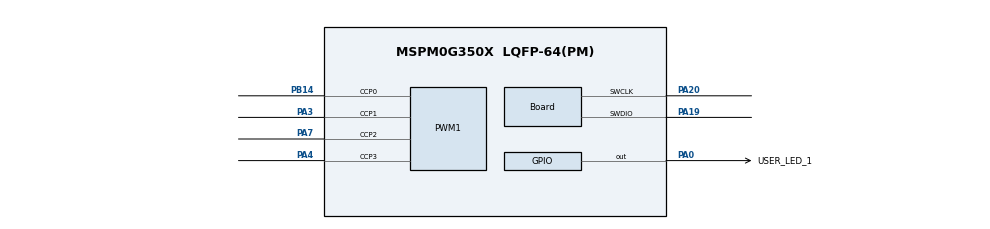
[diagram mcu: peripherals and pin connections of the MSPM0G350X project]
/**
 * @cliArgs --device "MSPM0G350X" --package "LQFP-64(PM)" --part "Default" --product "mspm0_sdk@2.01.00.03"
 * @versions {"tool":"1.20.0+3587"}
 */

/**
 * Import the modules used in this configuration.
 */
const Board         = scripting.addModule("/ti/driverlib/Board");
const GPIO          = scripting.addModule("/ti/driverlib/GPIO", {}, false);
const GPIO1         = GPIO.addInstance();
const GPIO2         = GPIO.addInstance();
const GPIO3         = GPIO.addInstance();
const PWM           = scripting.addModule("/ti/driverlib/PWM", {}, false);
const PWM1          = PWM.addInstance();
const SYSCTL        = scripting.addModule("/ti/driverlib/SYSCTL");
const TIMER         = scripting.addModule("/ti/driverlib/TIMER", {}, false);
const TIMER1        = TIMER.addInstance();
const ProjectConfig = scripting.addModule("/ti/project_config/ProjectConfig");

/**
 * Write custom configuration values to the imported modules.
 */
Board.peripheral.$assign          = "DEBUGSS";
Board.peripheral.swclkPin.$assign = "PA20";
Board.peripheral.swdioPin.$assign = "PA19";

GPIO1.port                           = "PORTA";
GPIO1.$name                          = "GPIO_LEDS_PORT";
GPIO1.portSegment                    = "Lower";
GPIO1.associatedPins[0].initialValue = "SET";
GPIO1.associatedPins[0].$name        = "USER_LED_1";
GPIO1.associatedPins[0].assignedPin  = "0";
GPIO1.associatedPins[0].pin.$assign  = "PA0";

GPIO2.$name                         = "GPIO_RGB";
GPIO2.port                          = "PORTB";
GPIO2.portSegment                   = "Upper";
GPIO2.associatedPins.create(3);
GPIO2.associatedPins[0].$name       = "RED";
GPIO2.associatedPins[0].assignedPin = "26";
GPIO2.associatedPins[1].$name       = "GREEN";
GPIO2.associatedPins[1].assignedPin = "27";
GPIO2.associatedPins[2].$name       = "BLUE";
GPIO2.associatedPins[2].assignedPin = "22";

GPIO3.$name                              = "GPIO_KEY";
GPIO3.port                               = "PORTB";
GPIO3.associatedPins.create(3);
GPIO3.associatedPins[0].$name            = "KEY_1";
GPIO3.associatedPins[0].direction        = "INPUT";
GPIO3.associatedPins[0].assignedPin      = "21";
GPIO3.associatedPins[0].internalResistor = "PULL_UP";
GPIO3.associatedPins[1].assignedPin      = "23";
GPIO3.associatedPins[1].$name            = "KEY_2";
GPIO3.associatedPins[1].direction        = "INPUT";
GPIO3.associatedPins[1].internalResistor = "PULL_UP";
GPIO3.associatedPins[2].assignedPin      = "24";
GPIO3.associatedPins[2].$name            = "KEY_3";
GPIO3.associatedPins[2].direction        = "INPUT";
GPIO3.associatedPins[2].internalResistor = "PULL_UP";

PWM1.ccIndex                            = [0,1,2,3];
PWM1.clockPrescale                      = 32;
PWM1.pwmMode                            = "EDGE_ALIGN_UP";
PWM1.$name                              = "CAR_PWM0";
PWM1.peripheral.$assign                 = "TIMA0";
PWM1.peripheral.ccp0Pin.$assign         = "PB14";
PWM1.peripheral.ccp1Pin.$assign         = "PA3";
PWM1.peripheral.ccp2Pin.$assign         = "PA7";
PWM1.peripheral.ccp3Pin.$assign         = "PA4";
PWM1.PWM_CHANNEL_0.$name                = "ti_driverlib_pwm_PWMTimerCC0";
PWM1.PWM_CHANNEL_1.$name                = "ti_driverlib_pwm_PWMTimerCC1";
PWM1.ccp0PinConfig.$name                = "ti_driverlib_gpio_GPIOPinGeneric0";
PWM1.ccp0PinConfig.direction            = scripting.forceWrite("OUTPUT");
PWM1.ccp0PinConfig.hideOutputInversion  = scripting.forceWrite(false);
PWM1.ccp0PinConfig.onlyInternalResistor = scripting.forceWrite(false);
PWM1.ccp0PinConfig.passedPeripheralType = scripting.forceWrite("Digital");
PWM1.ccp1PinConfig.$name                = "ti_driverlib_gpio_GPIOPinGeneric1";
PWM1.ccp1PinConfig.direction            = scripting.forceWrite("OUTPUT");
PWM1.ccp1PinConfig.hideOutputInversion  = scripting.forceWrite(false);
PWM1.ccp1PinConfig.onlyInternalResistor = scripting.forceWrite(false);
PWM1.ccp1PinConfig.passedPeripheralType = scripting.forceWrite("Digital");
PWM1.PWM_CHANNEL_2.$name                = "ti_driverlib_pwm_PWMTimerCC2";
PWM1.PWM_CHANNEL_2.invert               = true;
PWM1.PWM_CHANNEL_3.$name                = "ti_driverlib_pwm_PWMTimerCC3";
PWM1.PWM_CHANNEL_3.invert               = true;
PWM1.ccp2PinConfig.$name                = "ti_driverlib_gpio_GPIOPinGeneric2";
PWM1.ccp2PinConfig.direction            = scripting.forceWrite("OUTPUT");
PWM1.ccp2PinConfig.hideOutputInversion  = scripting.forceWrite(false);
PWM1.ccp2PinConfig.onlyInternalResistor = scripting.forceWrite(false);
PWM1.ccp2PinConfig.passedPeripheralType = scripting.forceWrite("Digital");
PWM1.ccp3PinConfig.$name                = "ti_driverlib_gpio_GPIOPinGeneric3";
PWM1.ccp3PinConfig.direction            = scripting.forceWrite("OUTPUT");
PWM1.ccp3PinConfig.hideOutputInversion  = scripting.forceWrite(false);
PWM1.ccp3PinConfig.onlyInternalResistor = scripting.forceWrite(false);
PWM1.ccp3PinConfig.passedPeripheralType = scripting.forceWrite("Digital");

SYSCTL.clockTreeEn = true;

TIMER1.$name              = "TIMER_0";
TIMER1.interrupts         = ["ZERO"];
TIMER1.timerMode          = "PERIODIC";
TIMER1.timerPeriod        = "1ms";
TIMER1.peripheral.$assign = "TIMG0";

ProjectConfig.deviceSpin = "MSPM0G3507";

/**
 * Pinmux solution for unlocked pins/peripherals. This ensures that minor changes to the automatic solver in a future
 * version of the tool will not impact the pinmux you originally saw.  These lines can be completely deleted in order to
 * re-solve from scratch.
 */
GPIO2.associatedPins[0].pin.$suggestSolution = "PB26";
GPIO2.associatedPins[1].pin.$suggestSolution = "PB27";
GPIO2.associatedPins[2].pin.$suggestSolution = "PB22";
GPIO3.associatedPins[0].pin.$suggestSolution = "PB21";
GPIO3.associatedPins[1].pin.$suggestSolution = "PB23";
GPIO3.associatedPins[2].pin.$suggestSolution = "PB24";
